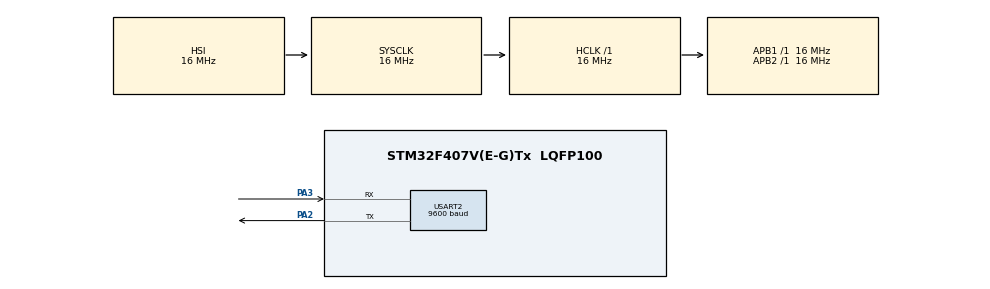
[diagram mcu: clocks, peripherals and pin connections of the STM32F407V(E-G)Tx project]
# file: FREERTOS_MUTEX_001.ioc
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FREERTOS.BinarySemaphores01=myBinarySem01,Dynamic,NULL
FREERTOS.Mutexes01=myMutex01,Dynamic,NULL
FREERTOS.Tasks01=Task1,1,128,StartTask1,Default,NULL,Dynamic,NULL,NULL;Task2,0,128,StartTask2,Default,NULL,Dynamic,NULL,NULL
FREERTOS.configUSE_NEWLIB_REENTRANT=1
Mcu.Family=STM32F4
Mcu.Name=STM32F407V(E-G)Tx
Mcu.Package=LQFP100
NVIC.PriorityGroup=NVIC_PRIORITYGROUP_4
NVIC.TIM2_IRQn=true\:15\:0\:false\:false\:true\:false\:false\:true\:true
NVIC.TimeBase=TIM2_IRQn
NVIC.TimeBaseIP=TIM2
PA13.Mode=Serial_Wire
PA13.Signal=SYS_JTMS-SWDIO
PA14.Mode=Serial_Wire
PA14.Signal=SYS_JTCK-SWCLK
PA2.Mode=Asynchronous
PA2.Signal=USART2_TX
PA3.Mode=Asynchronous
PA3.Signal=USART2_RX
PH0-OSC_IN.Mode=HSE-External-Oscillator
PH0-OSC_IN.Signal=RCC_OSC_IN
PH1-OSC_OUT.Mode=HSE-External-Oscillator
PH1-OSC_OUT.Signal=RCC_OSC_OUT
ProjectManager.HeapSize=0x200
ProjectManager.StackSize=0x400
ProjectManager.TargetToolchain=STM32CubeIDE
RCC.AHBFreq_Value=16000000
RCC.APB1Freq_Value=16000000
RCC.APB2Freq_Value=16000000
RCC.CortexFreq_Value=16000000
RCC.HSE_VALUE=25000000
RCC.HSI_VALUE=16000000
RCC.LSE_VALUE=32768
RCC.SYSCLKFreq_VALUE=16000000
RCC.VCOOutputFreq_Value=192000000
USART2.BaudRate=9600
USART2.VirtualMode=VM_ASYNC
VP_FREERTOS_VS_CMSIS_V1.Mode=CMSIS_V1
VP_SYS_VS_tim2.Mode=TIM2
board=custom

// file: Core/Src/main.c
/* USER CODE BEGIN Header */
/**
  ******************************************************************************
  * @file           : main.c
  * @brief          : Main program body
  ******************************************************************************
  * @attention
  *
  * Copyright (c) 2024 STMicroelectronics.
  * All rights reserved.
  *
  * This software is licensed under terms that can be found in the LICENSE file
  * in the root directory of this software component.
  * If no LICENSE file comes with this software, it is provided AS-IS.
  *
  ******************************************************************************
  */
/* USER CODE END Header */
#include "main.h"
#include "cmsis_os.h"

/* USER CODE BEGIN Includes */

#include "stdio.h"
#include "string.h"

/* USER CODE END Includes */

UART_HandleTypeDef huart2;

osThreadId Task1Handle;
osThreadId Task2Handle;
osMutexId myMutex01Handle;
osSemaphoreId myBinarySem01Handle;

void SystemClock_Config(void);
static void MX_GPIO_Init(void);
static void MX_USART2_UART_Init(void);
void StartTask1(void const * argument);
void StartTask2(void const * argument);

/* USER CODE BEGIN 0 */

char mySharedResource[5];
char TxData[2] = "\n\r";

/* USER CODE END 0 */

int main(void)
{

  /* MCU Configuration--------------------------------------------------------*/

  /* Reset of all peripherals, Initializes the Flash interface and the Systick. */
  HAL_Init();

  /* Configure the system clock */
  SystemClock_Config();

  /* Initialize all configured peripherals */
  MX_GPIO_Init();
  MX_USART2_UART_Init();

  /* Create the mutex(es) */
  /* definition and creation of myMutex01 */
  osMutexDef(myMutex01);
  myMutex01Handle = osMutexCreate(osMutex(myMutex01));

  /* Create the semaphores(s) */
  /* definition and creation of myBinarySem01 */
  osSemaphoreDef(myBinarySem01);
  myBinarySem01Handle = osSemaphoreCreate(osSemaphore(myBinarySem01), 1);

  /* Create the thread(s) */
  /* definition and creation of Task1 */
  osThreadDef(Task1, StartTask1, osPriorityAboveNormal, 0, 128);
  Task1Handle = osThreadCreate(osThread(Task1), NULL);

  /* definition and creation of Task2 */
  osThreadDef(Task2, StartTask2, osPriorityNormal, 0, 128);
  Task2Handle = osThreadCreate(osThread(Task2), NULL);

  /* Start scheduler */
  osKernelStart();

  /* We should never get here as control is now taken by the scheduler */
  /* Infinite loop */
  while (1)
  {

  }
}

void SystemClock_Config(void)
{
  RCC_OscInitTypeDef RCC_OscInitStruct = {0};
  RCC_ClkInitTypeDef RCC_ClkInitStruct = {0};

  /** Configure the main internal regulator output voltage
  */
  __HAL_RCC_PWR_CLK_ENABLE();
  __HAL_PWR_VOLTAGESCALING_CONFIG(PWR_REGULATOR_VOLTAGE_SCALE1);

  /** Initializes the RCC Oscillators according to the specified parameters
  * in the RCC_OscInitTypeDef structure.
  */
  RCC_OscInitStruct.OscillatorType = RCC_OSCILLATORTYPE_HSI;
  RCC_OscInitStruct.HSIState = RCC_HSI_ON;
  RCC_OscInitStruct.HSICalibrationValue = RCC_HSICALIBRATION_DEFAULT;
  RCC_OscInitStruct.PLL.PLLState = RCC_PLL_NONE;
  if (HAL_RCC_OscConfig(&RCC_OscInitStruct) != HAL_OK)
  {
    Error_Handler();
  }

  /** Initializes the CPU, AHB and APB buses clocks
  */
  RCC_ClkInitStruct.ClockType = RCC_CLOCKTYPE_HCLK|RCC_CLOCKTYPE_SYSCLK
                              |RCC_CLOCKTYPE_PCLK1|RCC_CLOCKTYPE_PCLK2;
  RCC_ClkInitStruct.SYSCLKSource = RCC_SYSCLKSOURCE_HSI;
  RCC_ClkInitStruct.AHBCLKDivider = RCC_SYSCLK_DIV1;
  RCC_ClkInitStruct.APB1CLKDivider = RCC_HCLK_DIV1;
  RCC_ClkInitStruct.APB2CLKDivider = RCC_HCLK_DIV1;

  if (HAL_RCC_ClockConfig(&RCC_ClkInitStruct, FLASH_LATENCY_0) != HAL_OK)
  {
    Error_Handler();
  }
}

static void MX_USART2_UART_Init(void)
{

  huart2.Instance = USART2;
  huart2.Init.BaudRate = 9600;
  huart2.Init.WordLength = UART_WORDLENGTH_8B;
  huart2.Init.StopBits = UART_STOPBITS_1;
  huart2.Init.Parity = UART_PARITY_NONE;
  huart2.Init.Mode = UART_MODE_TX_RX;
  huart2.Init.HwFlowCtl = UART_HWCONTROL_NONE;
  huart2.Init.OverSampling = UART_OVERSAMPLING_16;
  if (HAL_UART_Init(&huart2) != HAL_OK)
  {
    Error_Handler();
  }

}

static void MX_GPIO_Init(void)
{

  /* GPIO Ports Clock Enable */
  __HAL_RCC_GPIOH_CLK_ENABLE();
  __HAL_RCC_GPIOA_CLK_ENABLE();

}

void StartTask1(void const * argument)
{
  /* USER CODE BEGIN 5 */
	char Task1Msg[] = "Hello";

	/* Infinite loop */

	for(;;)
	{
		if(xSemaphoreTake(myMutex01Handle,1000))
		{
			int i;
			for(i = 0;i < 5;i++)
			{
				mySharedResource[i] = Task1Msg[i];
				vTaskDelay(50);
			}
		}
		HAL_UART_Transmit(&huart2, (uint8_t *)&mySharedResource, sizeof(mySharedResource),1000);
		HAL_UART_Transmit(&huart2, (uint8_t *)&TxData,sizeof(TxData),1000);
		xSemaphoreGive(myMutex01Handle);

		 vTaskDelay(2000);
	}
  /* USER CODE END 5 */
}

void StartTask2(void const * argument)
{
  /* USER CODE BEGIN StartTask2 */

	char Task2Msg[] = "World";
    // "tomatoes"

	/* Infinite loop */
	for(;;)
	{
		if(xSemaphoreTake(myMutex01Handle,1000))
		{
			int i;
			for(i = 0;i < 5;i++)
			{
				mySharedResource[i] = Task2Msg[i];
				vTaskDelay(50);
			}
		}
		HAL_UART_Transmit(&huart2, (uint8_t *)&mySharedResource, sizeof(mySharedResource),1000);
		HAL_UART_Transmit(&huart2, (uint8_t *)&TxData,sizeof(TxData),1000);
		xSemaphoreGive(myMutex01Handle);

		vTaskDelay(2000);
	}
  /* USER CODE END StartTask2 */
}

void HAL_TIM_PeriodElapsedCallback(TIM_HandleTypeDef *htim)
{
  if (htim->Instance == TIM2) {
    HAL_IncTick();
  }
}

void Error_Handler(void)
{
  __disable_irq();
  while (1)
  {
  }
}
